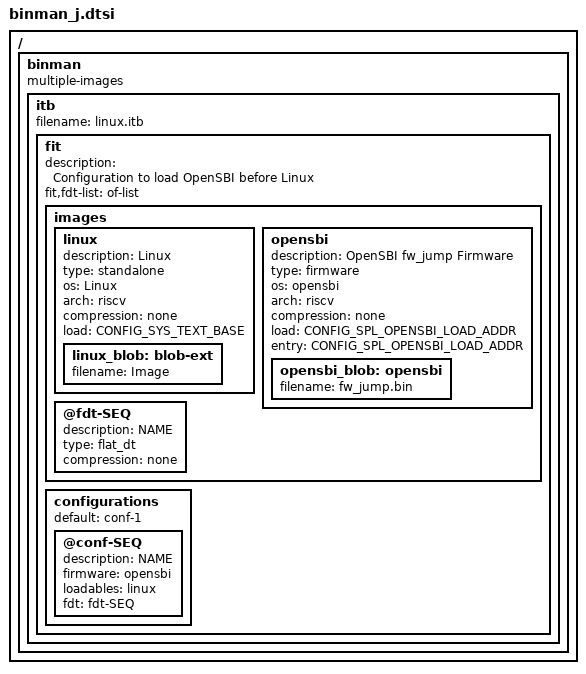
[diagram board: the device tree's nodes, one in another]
// SPDX-License-Identifier: GPL-2.0+
/*
 * Copyright (C) 2021, Bin Meng <bmeng.cn@gmail.com>
 */

#include <config.h>

/ {
	binman: binman {
		multiple-images;
	};
};

&binman {
	itb {
		filename = "linux.itb";

		fit {
			description = "Configuration to load OpenSBI before Linux";
			#address-cells = <1>;
			fit,fdt-list = "of-list";

			images {
				linux {
					description = "Linux";
					type = "standalone";
					os = "Linux";
					arch = "riscv";
					compression = "none";
					load = <CONFIG_SYS_TEXT_BASE>;

					linux_blob: blob-ext {
						filename = "Image";
					};
				};

				opensbi {
					description = "OpenSBI fw_jump Firmware";
					type = "firmware";
					os = "opensbi";
					arch = "riscv";
					compression = "none";
					load = <CONFIG_SPL_OPENSBI_LOAD_ADDR>;
					entry = <CONFIG_SPL_OPENSBI_LOAD_ADDR>;

					opensbi_blob: opensbi {
						filename = "fw_jump.bin";
					};
				};

#ifndef CONFIG_OF_BOARD
				@fdt-SEQ {
					description = "NAME";
					type = "flat_dt";
					compression = "none";
				};
#endif
			};

			configurations {
				default = "conf-1";

#ifndef CONFIG_OF_BOARD
				@conf-SEQ {
#else
				conf-1 {
#endif
					description = "NAME";
					firmware = "opensbi";
					loadables = "linux";
#ifndef CONFIG_OF_BOARD
					fdt = "fdt-SEQ";
#endif
				};
			};
		};
	};
};
